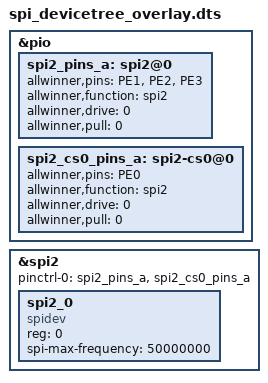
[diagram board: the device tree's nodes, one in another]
/dts-v1/;
/plugin/;

/ {
	/*
	 * Enable our SPI device, with an spidev device connected
	 * to it
	*/

	fragment@0 {
		target = <&pio>;

		__overlay__ {
			spi2_pins_a: spi2@0 {
				allwinner,pins = "PE1", "PE2", "PE3";
				allwinner,function = "spi2";
				allwinner,drive = <0>;
				allwinner,pull = <0>;
			};

			spi2_cs0_pins_a: spi2-cs0@0 {
				allwinner,pins = "PE0";
				allwinner,function = "spi2";
				allwinner,drive = <0>;
				allwinner,pull = <0>;
			};
		};
	};

	fragment@1 {
		target=<&spi2>;

		__overlay__ {
				status = "okay";
				pinctrl-0 = <&spi2_pins_a>, <&spi2_cs0_pins_a>;

				spi2_0 {
					#address-cells = <1>;
					#size-cells = <0>;

					compatible = "spidev";

					reg = <0>;
					spi-max-frequency = <50000000>;
			};
		};
	};
};
